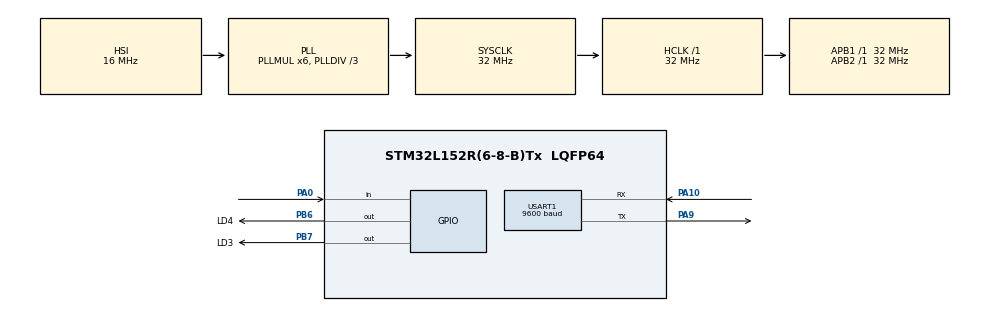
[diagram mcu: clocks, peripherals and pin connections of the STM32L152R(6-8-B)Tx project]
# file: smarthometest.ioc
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Mcu.Family=STM32L1
Mcu.Name=STM32L152R(6-8-B)Tx
Mcu.Package=LQFP64
NVIC.PriorityGroup=NVIC_PRIORITYGROUP_4
NVIC.USART1_IRQn=true\:0\:0\:false
PA0-WKUP1.Signal=GPIO_Input
PA10.Mode=Asynchronous
PA10.Signal=USART1_RX
PA9.Mode=Asynchronous
PA9.Signal=USART1_TX
PB6.GPIO_Label=LD4
PB6.Signal=GPIO_Output
PB7.GPIO_Label=LD3
PB7.Signal=GPIO_Output
PH0-OSC_IN.Mode=HSE-External-Oscillator
PH0-OSC_IN.Signal=RCC_OSC_IN
PH1-OSC_OUT.Mode=HSE-External-Oscillator
PH1-OSC_OUT.Signal=RCC_OSC_OUT
ProjectManager.TargetToolchain=EWARM
RCC.AHBFreq_Value=32000000
RCC.APB1Freq_Value=32000000
RCC.APB1TimFreq_Value=32000000
RCC.APB2Freq_Value=32000000
RCC.APB2TimFreq_Value=32000000
RCC.HCLKFreq_Value=32000000
RCC.HSE_VALUE=8000000
RCC.HSI_VALUE=16000000
RCC.LSE_VALUE=32768
RCC.MSI_VALUE=2097000
RCC.PLLDIV=RCC_PLL_DIV3
RCC.PLLMUL=RCC_PLL_MUL6
RCC.SYSCLKFreq_VALUE=32000000
RCC.SYSCLKSource=RCC_SYSCLKSOURCE_PLLCLK
RCC.USBOutput=48000000
RCC.VCOOutputFreq_Value=96000000
USART1.BaudRate=9600
board=smarthometest

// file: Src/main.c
/**
  ******************************************************************************
  * File Name          : main.c
  * Description        : Main program body
  ******************************************************************************
  *
  * COPYRIGHT(c) 2016 STMicroelectronics
  *
  * Redistribution and use in source and binary forms, with or without modification,
  * are permitted provided that the following conditions are met:
  *   1. Redistributions of source code must retain the above copyright notice,
  *      this list of conditions and the following disclaimer.
  *   2. Redistributions in binary form must reproduce the above copyright notice,
  *      this list of conditions and the following disclaimer in the documentation
  *      and/or other materials provided with the distribution.
  *   3. Neither the name of STMicroelectronics nor the names of its contributors
  *      may be used to endorse or promote products derived from this software
  *      without specific prior written permission.
  *
  * THIS SOFTWARE IS PROVIDED BY THE COPYRIGHT HOLDERS AND CONTRIBUTORS "AS IS"
  * AND ANY EXPRESS OR IMPLIED WARRANTIES, INCLUDING, BUT NOT LIMITED TO, THE
  * IMPLIED WARRANTIES OF MERCHANTABILITY AND FITNESS FOR A PARTICULAR PURPOSE ARE
  * DISCLAIMED. IN NO EVENT SHALL THE COPYRIGHT HOLDER OR CONTRIBUTORS BE LIABLE
  * FOR ANY DIRECT, INDIRECT, INCIDENTAL, SPECIAL, EXEMPLARY, OR CONSEQUENTIAL
  * DAMAGES (INCLUDING, BUT NOT LIMITED TO, PROCUREMENT OF SUBSTITUTE GOODS OR
  * SERVICES; LOSS OF USE, DATA, OR PROFITS; OR BUSINESS INTERRUPTION) HOWEVER
  * CAUSED AND ON ANY THEORY OF LIABILITY, WHETHER IN CONTRACT, STRICT LIABILITY,
  * OR TORT (INCLUDING NEGLIGENCE OR OTHERWISE) ARISING IN ANY WAY OUT OF THE USE
  * OF THIS SOFTWARE, EVEN IF ADVISED OF THE POSSIBILITY OF SUCH DAMAGE.
  *
  ******************************************************************************
  */
#include "stm32l1xx_hal.h"
#include "usart.h"
#include "gpio.h"

/* USER CODE BEGIN Includes */
#include "include.h"
/* USER CODE END Includes */

/* USER CODE BEGIN PV */
/* Private variables ---------------------------------------------------------*/

/* USER CODE END PV */

void SystemClock_Config(void);

/* USER CODE BEGIN PFP */
/* Private function prototypes -----------------------------------------------*/

/* USER CODE END PFP */

int main(void)
{

  /* MCU Configuration----------------------------------------------------------*/

  /* Reset of all peripherals, Initializes the Flash interface and the Systick. */
  HAL_Init();

  /* Configure the system clock */
  SystemClock_Config();

  /* Initialize all configured peripherals */
  MX_GPIO_Init();
  MX_USART1_UART_Init();

  /* USER CODE BEGIN 2 */
	HardInit();
	ParaInit();
	printf("�豸������\r\n");
  /* USER CODE END 2 */

  /* Infinite loop */
  while (1)
  {

  /* USER CODE BEGIN 3 */
	MainHandle();
  }
  /* USER CODE END 3 */

}

/** System Clock Configuration
*/
void SystemClock_Config(void)
{

  RCC_OscInitTypeDef RCC_OscInitStruct;
  RCC_ClkInitTypeDef RCC_ClkInitStruct;

  __PWR_CLK_ENABLE();

  __HAL_PWR_VOLTAGESCALING_CONFIG(PWR_REGULATOR_VOLTAGE_SCALE1);

  RCC_OscInitStruct.OscillatorType = RCC_OSCILLATORTYPE_HSI;
  RCC_OscInitStruct.HSIState = RCC_HSI_ON;
  RCC_OscInitStruct.HSICalibrationValue = 16;
  RCC_OscInitStruct.PLL.PLLState = RCC_PLL_ON;
  RCC_OscInitStruct.PLL.PLLSource = RCC_PLLSOURCE_HSI;
  RCC_OscInitStruct.PLL.PLLMUL = RCC_PLL_MUL6;
  RCC_OscInitStruct.PLL.PLLDIV = RCC_PLL_DIV3;
  HAL_RCC_OscConfig(&RCC_OscInitStruct);

  RCC_ClkInitStruct.ClockType = RCC_CLOCKTYPE_SYSCLK;
  RCC_ClkInitStruct.SYSCLKSource = RCC_SYSCLKSOURCE_PLLCLK;
  RCC_ClkInitStruct.AHBCLKDivider = RCC_SYSCLK_DIV1;
  RCC_ClkInitStruct.APB1CLKDivider = RCC_HCLK_DIV1;
  RCC_ClkInitStruct.APB2CLKDivider = RCC_HCLK_DIV1;
  HAL_RCC_ClockConfig(&RCC_ClkInitStruct, FLASH_LATENCY_1);

  HAL_SYSTICK_Config(HAL_RCC_GetHCLKFreq()/1000);

  HAL_SYSTICK_CLKSourceConfig(SYSTICK_CLKSOURCE_HCLK);

  /* SysTick_IRQn interrupt configuration */
  HAL_NVIC_SetPriority(SysTick_IRQn, 0, 0);
}

/************************ (C) COPYRIGHT STMicroelectronics *****END OF FILE****/
